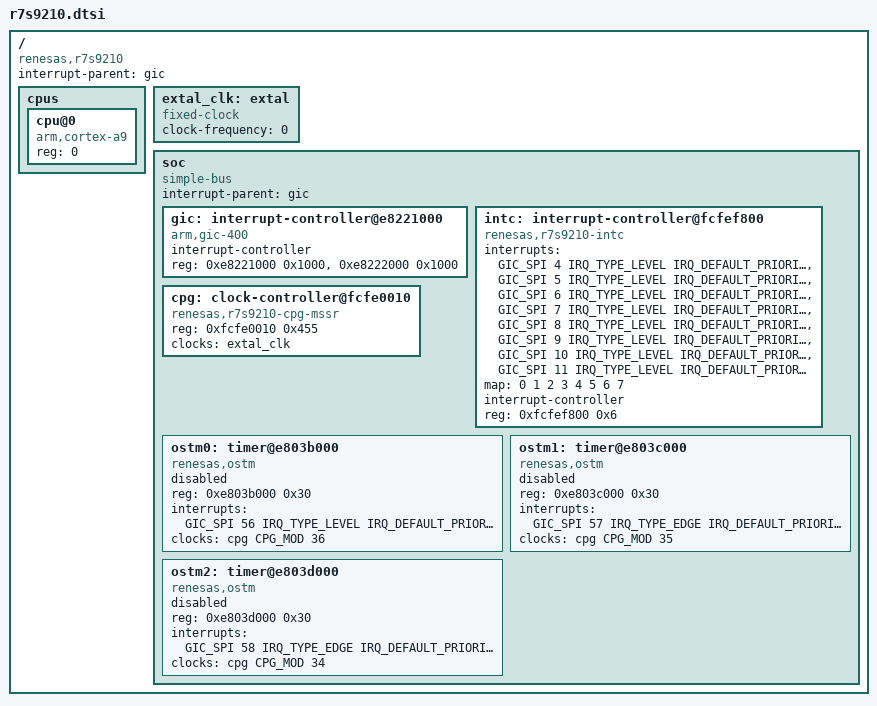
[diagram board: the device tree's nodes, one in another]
/*
 * Copyright (c) 2023 EPAM Systems
 *
 * SPDX-License-Identifier: Apache-2.0
 */

#include <mem.h>
#include <arm/armv7-a.dtsi>
#include <zephyr/dt-bindings/interrupt-controller/arm-gic.h>
#include <zephyr/dt-bindings/interrupt-controller/r7s9210-intc.h>
#include <zephyr/dt-bindings/clock/renesas_cpg_mssr.h>
#include <zephyr/dt-bindings/clock/r7s9210_cpg_mssr.h>

/ {
	compatible = "renesas,r7s9210";
	interrupt-parent = <&gic>;
	#address-cells = <1>;
	#size-cells = <1>;

	cpus {
		#address-cells = <1>;
		#size-cells = <0>;

		cpu@0 {
			device_type = "cpu";
			compatible = "arm,cortex-a9";
			reg = <0>;
		};
	};

	extal_clk: extal {
		#clock-cells = <0>;
		compatible = "fixed-clock";
		/* Value must be set by board */
		clock-frequency = <0>;
	};

	soc {
		compatible = "simple-bus";
		interrupt-parent = <&gic>;

		#address-cells = <1>;
		#size-cells = <1>;
		ranges;

		gic: interrupt-controller@e8221000 {
			compatible = "arm,gic-400", "arm,gic-v2", "arm,gic";
			#interrupt-cells = <4>;
			#address-cells = <0>;
			interrupt-controller;
			reg = <0xe8221000 0x1000>,
			      <0xe8222000 0x1000>;
		};

		intc: interrupt-controller@fcfef800 {
			compatible = "renesas,r7s9210-intc";
			#interrupt-cells = <2>;
			#address-cells = <0>;
			interrupts =
				<GIC_SPI 4  IRQ_TYPE_LEVEL IRQ_DEFAULT_PRIORITY>,
				<GIC_SPI 5  IRQ_TYPE_LEVEL IRQ_DEFAULT_PRIORITY>,
				<GIC_SPI 6  IRQ_TYPE_LEVEL IRQ_DEFAULT_PRIORITY>,
				<GIC_SPI 7  IRQ_TYPE_LEVEL IRQ_DEFAULT_PRIORITY>,
				<GIC_SPI 8  IRQ_TYPE_LEVEL IRQ_DEFAULT_PRIORITY>,
				<GIC_SPI 9  IRQ_TYPE_LEVEL IRQ_DEFAULT_PRIORITY>,
				<GIC_SPI 10 IRQ_TYPE_LEVEL IRQ_DEFAULT_PRIORITY>,
				<GIC_SPI 11 IRQ_TYPE_LEVEL IRQ_DEFAULT_PRIORITY>;
			map = <0 1 2 3 4 5 6 7>;
			interrupt-controller;
			reg = <0xfcfef800 0x6>;
		};

		cpg: clock-controller@fcfe0010 {
			compatible = "renesas,r7s9210-cpg-mssr";
			reg = <0xfcfe0010 0x455>;
			#clock-cells = <2>;
			clocks = <&extal_clk>;
		};

		ostm0: timer@e803b000 {
			compatible = "renesas,ostm";
			reg = <0xe803b000 0x30>;
			interrupts = <GIC_SPI 56 IRQ_TYPE_LEVEL IRQ_DEFAULT_PRIORITY>;
			clocks = <&cpg CPG_MOD 36>;
			status = "disabled";
		};

		ostm1: timer@e803c000 {
			compatible = "renesas,ostm";
			reg = <0xe803c000 0x30>;
			interrupts = <GIC_SPI 57 IRQ_TYPE_EDGE IRQ_DEFAULT_PRIORITY>;
			clocks = <&cpg CPG_MOD 35>;
			status = "disabled";
		};

		ostm2: timer@e803d000 {
			compatible = "renesas,ostm";
			reg = <0xe803d000 0x30>;
			interrupts = <GIC_SPI 58 IRQ_TYPE_EDGE IRQ_DEFAULT_PRIORITY>;
			clocks = <&cpg CPG_MOD 34>;
			status = "disabled";
		};
	};
};
